# STM32U345 register map
File version: 1.0
CPU: CM33 r0p1, little endian, MPU, FPU, 4 interrupt priority bits
Registers are 32-bit, read-write, reset 0x0 unless marked. A register's access mark holds for its fields unless they carry their own. Offsets are from the block's base; [hi:lo] are bit positions; {n}, {i} and the like mark numbered series.

## SYSCFG — SYSCFG register block
Base 0x40040400
Same registers: SYSCFG_S 0x50040400
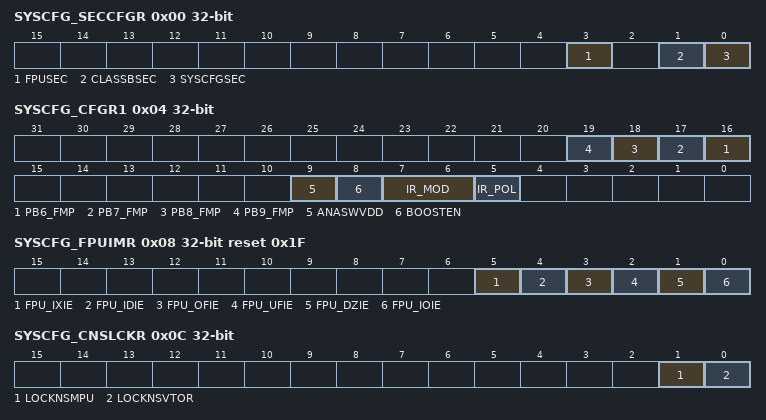
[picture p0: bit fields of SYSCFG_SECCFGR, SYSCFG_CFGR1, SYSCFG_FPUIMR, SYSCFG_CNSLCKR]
0x00 SYSCFG_SECCFGR — When the system is secure (TZEN = 1), this register provides write access security and can be written only when the access is secure. This register can be globally write-protected. Each bit can be individually write-protected. A nonsecure write access is WI and generates an illegal access event. There are no read restrictions. When the system is not secure (TZEN = 0), this register is RAZ/WI. This register can be read and written by privileged and unprivileged access, except for FPUSEC that can be written only with privileged access.
  [3] FPUSEC — FPU security
    0=SYSCFG_FPUIMR can be read and written by secure and nonsecure access; 1=SYSCFG_FPUIMR can be read and written by secure access only
  [1] CLASSBSEC — Class B security
    0=SYSCFG_CFGR2 can be read and written by secure and nonsecure access; 1=SYSCFG_CFGR2 can be read and written by secure access only
  [0] SYSCFGSEC — Security of SYSCFG clock control, memory erase status, and compensation cell registers
    0=SYSCFG configuration clock in RCC registers and SYSCFG_CCCSR, SYSCFG_CCVR, and SYSCFG_CCCR can be read and written by secure and nonsecure access; 1=SYSCFG configuration clock in RCC registers and SYSCFG_CCCSR, SYSCFG_CCVR, and SYSCFG_CCCR can be read and written by secure access only
0x04 SYSCFG_CFGR1 — When the system is secure (TZEN = 1), this register can be a mix of secure and nonsecure bits depending on the ADC and the TSC security configuration bit in GTZC peripheral and GPIO security bits. A nonsecure read/write access on secured bits is RAZ/WI. When the system is not secure (TZEN = 0), there is no access restriction. This register can be read and written by privileged and unprivileged access.
  [n+10] PB{n}_FMP (n=6..9) — Fast-mode Plus driving capability activation on PBi This bit can be read and written only with secure access if PB9 is secure in GPIOB. This bit enables the Fm+ driving mode for PBi when PBi is not used by the I2C peripheral. This can be used to drive a LED for instance.
    0=PBi pin operates in standard mode; 1=Fm+ mode is enabled on PBi pin and the speed control is bypassed
  [9] ANASWVDD — GPIO analog switch control voltage selection This bit can be read and written only with secure access if ADC1 or ADC2 is secure in GTZC. Note: Refer to Table 114: BOOSTEN and ANASWVDD set/reset
    0=I/O analog switches are supplied by V<sub>DDA</sub> or booster when booster is ON; 1=I/O analog switches are supplied by V<sub>DD</sub>
  [8] BOOSTEN — I/O analog switch voltage booster enable This bit can be read and written only with secure access if ADC1 or ADC2 is secure in GTZC. Note: Refer to Table 114: BOOSTEN and ANASWVDD set/reset
    0=I/O analog switches are supplied by V<sub>DDA</sub> voltage; 1=I/O analog switches are supplied by a dedicated voltage booster (supplied by V<sub>DD</sub>)
  [7:6] IR_MOD — IR modulation envelope signal selection This bit field can be read and written only with secure access if TIM17 is secure in GTZC. It selects the signal for IR modulation envelope. Note: Refer to Table 114: BOOSTEN and ANASWVDD set/reset.
    0=TIM16; 1=USART1; 2=UART4
  [5] IR_POL — IR output polarity selection This bit can be read and written only with secure access if TIM17 is secure in GTZC. Note: Refer to Table 114: BOOSTEN and ANASWVDD set/reset.
    0=Output of IRTIM (IR_OUT) is not inverted; 1=Output of IRTIM (IR_OUT) is inverted
0x08 SYSCFG_FPUIMR reset 0x1F — When the system is secure (TZEN = 1), this register can be protected against nonsecure access by setting the FPUSEC bit in the SYSCFG_SECCFGR register: a nonsecure read/write access is RAZ/WI and generates an illegal access event. When the system is not secure (TZEN = 0), there is no access restriction. This register can be read and written by privileged access only. Unprivileged access is RAZ/WI.
  [all] fields
    0=Interrupt disabled; 1=Interrupt enabled
  [5] FPU_IXIE — Floating point unit interrupt enable bit - inexact FPU inexact interrupt enable bit (interrupt disable at reset)
  [4] FPU_IDIE — Floating point unit interrupt enable bit - input denormal FPU denormal interrupt enable bit
  [3] FPU_OFIE — Floating point unit interrupt enable bit - overflow FPU overflow interrupt enable bit
  [2] FPU_UFIE — Floating point unit interrupt enable bit - underflow FPU underflow interrupt enable bit
  [1] FPU_DZIE — Floating point unit interrupt enable bit - divide-by-zero FPU divide-by-zero interrupt enable bit
  [0] FPU_IOIE — Floating point unit interrupt enable bit - invalid operation FPU invalid operation interrupt enable bit
0x0C SYSCFG_CNSLCKR — This register is used to lock the configuration of nonsecure MPU and VTOR_NS registers. This register can be read and written by privileged access only. Unprivileged access is RAZ/WI.
  [1] LOCKNSMPU — Nonsecure MPU registers lock This bit is set by software and cleared only by a system reset. When set, this bit disables write access to nonsecure MPU_CTRL_NS, MPU_RNR_NS, and MPU_RBAR_NS registers.
    0=Nonsecure MPU register write enabled; 1=Nonsecure MPU register write disabled
  [0] LOCKNSVTOR — VTOR_NS register lock This bit is set by software and cleared only by a system reset.
    0=VTOR_NS register write enabled; 1=VTOR_NS register write disabled
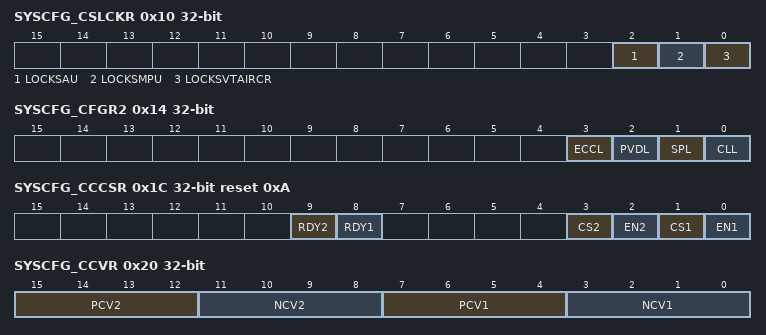
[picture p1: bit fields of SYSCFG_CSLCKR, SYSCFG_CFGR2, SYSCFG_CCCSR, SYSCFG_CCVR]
0x10 SYSCFG_CSLCKR — This register is used to lock the configuration of PRIS and BFHFNMINS in AIRCR register, SAU, secure MPU, and VTOR_S registers. When the system is secure (TZEN = 1), this register can be written only when the access is secure. A nonsecure read/write access is RAZ/WI and generates an illegal access event. When the system is not secure (TZEN = 0), this register is RAZ/WI. This register can be read and written by privileged access only. Unprivileged access is RAZ/WI.
  [2] LOCKSAU — SAU register lock This bit is set by software and cleared only by a system reset. When set, this bit disables write access to SAU_CTRL, SAU_RNR, SAU_RBAR, and SAU_RLAR registers.
    0=SAU register write enabled; 1=SAU register write disabled
  [1] LOCKSMPU — Secure MPU registers lock This bit is set by software and cleared only by a system reset. When set, this bit disables write access to secure MPU_CTRL, MPU_RNR, and MPU_RBAR registers.
    0=Secure MPU register writes enabled; 1=Secure MPU register writes disabled
  [0] LOCKSVTAIRCR — VTOR_S register and AIRCR register bits lock This bit is set by software and cleared only by a system reset. When set, this bit disables write access to VTOR_S register, PRIS and BFHFNMINS bits in the AIRCR register.
    0=VTOR_S register PRIS and BFHFNMINS bits in AIRCR register write enabled; 1=VTOR_S register PRIS and BFHFNMINS bits in AIRCR register write disabled
0x14 SYSCFG_CFGR2 — When the system is secure (TZEN = 1), this register can be protected against nonsecure access by setting the CLASSBSEC bit in the SYSCFG_SECCFGR register. When CLASSBSEC bit is set, only secure access is allowed: nonsecure read/write access is RAZ/WI and generates an illegal access event. When the system is not secure (TZEN = 0), there is no access restriction. This register can be read and written by privileged and unprivileged access.
  [3] ECCL — ECC lock This bit is set by software and cleared only by a system reset. It can be used to enable and lock the FLASH ECC double error signal connection to the TIM1/8/15/16/17 break input. Note: TIM8 is only available on STM32U3B5/3C5.
    0=ECC double error disconnected from TIM1/8/15/16/17 break input; 1=ECC double error connected to TIM1/8/15/16/17 break input
  [2] PVDL — PVD lock enable bit This bit is set by software and cleared only by a system reset. It can be used to enable and lock the PVD connection to TIM1/8/15/16/17 break input, as well as the PVDE and PVDLS[2:0] in the PWR register. Note: TIM8 is only available on STM32U3B5/3C5.
    0=PVD interrupt disconnected from TIM1/8/15/16/17 break input. PVDE and PVDLS[2:0] bits can be programmed by the application.; 1=PVD interrupt connected to TIM1/8/15/16/17 break input. PVDE and PVDLS[2:0] bits are read only.
  [1] SPL — SRAM2 parity bit This bit is set by the software and cleared only by a system reset. It can be used to enable and lock the SRAM2 parity error signal connection to TIM1/8/15/16/17 break inputs. Note: TIM8 is only available on STM32U3B5/3C5.
    0=SRAM double error disconnected from TIM1/8/15/16/17 break inputs; 1=SRAM double error connected to TIM1/8/15/16/17 break inputs
  [0] CLL — Cortex-M33 LOCKUP (HardFault) output enable This bit is set by the software and cleared only by a system reset. It can be used to enable and lock the connection of Cortex-M33 LOCKUP (HardFault) output to TIM1/15/16/17 break input. Note: TIM8 is only available on STM32U3B5/3C5.
    0=Cortex-M33 LOCKUP output disconnected from TIM1/8/15/16/17 break inputs; 1=Cortex-M33 LOCKUP output connected to TIM1/8/15/16/17 break inputs
0x1C SYSCFG_CCCSR reset 0xA — When the system is secure (TZEN = 1), this register can be protected against nonsecure access by setting the SYSCFGSEC bit in SYSCFG_SECCFGR register. When the SYSCFGSEC bit is set, only secure access is allowed: nonsecure read/write access is RAZ/WI and generates an illegal access event. When the system is not secure (TZEN = 0), there is no access restriction. This register can be read and written by privileged and unprivileged access.
  [9] RDY2 ro — VDDIO2 I/O compensation cell ready flag This bit provides the compensation cell status of the I/Os supplied by V<sub>DDIO2</sub>. Note: The HSI clock is required for the compensation cell to work properly. The compensation cell ready bit (RDY2) is not set if the HSI clock is not enabled.
    0=VDDIO2 I/O compensation cell not ready; 1=VDDIO2 I/O compensation cell ready
  [8] RDY1 ro — VDD I/O compensation cell ready flag This bit provides the compensation cell status of the I/Os supplied by V<sub>DD</sub>. Note: The HSI clock is required for the compensation cell to work properly. The compensation cell ready bit (RDY1) is not set if the HSI clock is not enabled.
    0=VDD I/O compensation cell not ready; 1=VDD I/O compensation cell ready
  [3] CS2 — VDDIO2 I/O code selection This bit selects the code to be applied for the compensation cell of the I/Os supplied by V<sub>DDIO2</sub>.
    0=VDDIO2 I/O code from the cell (available in SYSCFG_CCVR); 1=VDDIO2 I/O code from SYSCFG_CCCR
  [2] EN2 — VDDIO2 I/O compensation cell enable This bit enables the compensation cell of the I/Os supplied by V<sub>DDIO2</sub>.
    0=VDDIO2 I/O compensation cell disabled; 1=VDDIO2 I/O compensation cell enabled
  [1] CS1 — VDD I/O code selection This bit selects the code to be applied for the compensation cell of the I/Os supplied by V<sub>DD</sub>.
    0=VDD I/O code from the cell (available in the SYSCFG_CCVR); 1=VDD I/O code from the SYSCFG compensation cell code register (SYSCFG_CCCR)
  [0] EN1 — VDD I/O compensation cell enable This bit enables the compensation cell of the I/Os supplied by V<sub>DD</sub>.
    0=VDD I/O compensation cell disabled; 1=VDD I/O compensation cell enabled
0x20 SYSCFG_CCVR ro — When the system is secure (TZEN = 1), this register can be protected against nonsecure access by setting the SYSCFGSEC bit in the SYSCFG_SECCFGR register. When the SYSCFGSEC bit is set, only secure access is allowed: nonsecure read/write access is RAZ/WI and generates an illegal access event. When the system is not secure (TZEN = 0), there is no access restriction. This register can be read and written by privileged and unprivileged access.
  [15:12] PCV2 — PMOS compensation value of the I/Os supplied by V<sub>DDIO2</sub> This value is provided by the cell and can be used by the CPU to compute an I/O compensation cell code for PMOS transistors. This code is applied to the I/O compensation cell when CS2 bit in SYSCFG_CCCSR is reset.
  [11:8] NCV2 — NMOS compensation value of the I/Os supplied by V<sub>DDIO2</sub> This value is provided by the cell and can be used by the CPU to compute an I/O compensation cell code for NMOS transistors. This code is applied to the I/O compensation cell when CS2 bit in SYSCFG_CCCSR is reset.
  [7:4] PCV1 — PMOS compensation value of the I/Os supplied by V<sub>DD</sub> This value is provided by the cell and can be used by the CPU to compute an I/O compensation cell code for PMOS transistors. This code is applied to the I/O compensation cell when CS1 bit in SYSCFG_CCCSR is reset.
  [3:0] NCV1 — NMOS compensation value of the I/Os supplied by V<sub>DD</sub> This value is provided by the cell and can be used by the CPU to compute an I/O compensation cell code for NMOS transistors. This code is applied to the I/O compensation cell when CS1 bit in SYSCFG_CCCSR is reset.
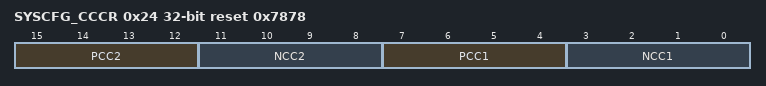
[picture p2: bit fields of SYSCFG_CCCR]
0x24 SYSCFG_CCCR reset 0x7878 — When the system is secure (TZEN = 1), this register can be protected against nonsecure access by setting the SYSCFGSEC bit in the SYSCFG_SECCFGR register. When SYSCFGSEC bit is set, only secure access is allowed: nonsecure read/write access is RAZ/WI and generates an illegal access event. When the system is not secure (TZEN = 0), there is no access restriction. This register can be read and written by privileged and unprivileged access.
  [15:12] PCC2 — PMOS compensation code of the I/Os supplied by V<sub>DDIO2</sub> These bits are written by software to define an I/O compensation cell code for PMOS transistors. This code is applied to the I/O compensation cell when CS2 bit is set in SYSCFG_CCCSR.
  [11:8] NCC2 — NMOS compensation code of the I/Os supplied by V<sub>DDIO2</sub> These bits are written by software to define an I/O compensation cell code for NMOS transistors. This code is applied to the I/O compensation cell when CS2 bit is set in SYSCFG_CCCSR.
  [7:4] PCC1 — PMOS compensation code of the I/Os supplied by V<sub>DD</sub> These bits are written by software to define an I/O compensation cell code for PMOS transistors. This code is applied to the I/O compensation cell when CS1 bit is set in SYSCFG_CCCSR.
  [3:0] NCC1 — NMOS compensation code of the I/Os supplied by V<sub>DD</sub> These bits are written by software to define an I/O compensation cell code for NMOS transistors. This code is applied to the I/O compensation cell when CS1 bit is set in SYSCFG_CCCSR.
0x2C SYSCFG_RSSCMDR — Power-on reset System reset value: 0xUUUU UUUU (not affected) When the system is secure (TZEN = 1), this register can be read and written only when the APB access is secure. Otherwise it is RAZ/WI. When the system is not secure (TZEN = 0), this register is RAZ/WI. This register can be read and written by privileged and unprivileged access.
  [15:0] RSSCMD — RSS commands This bit field defines a command to be executed by the RSS.
